# sir_me14 register map
Registers are read-only, no defined reset value unless marked. A register's access mark holds for its fields unless they carry their own. Offsets are from the block's base; lines under a group give offsets from that group; [hi:lo] are bit positions; {n}, {i} and the like mark numbered series; 'fields as' and 'values as' point back to an identical list; <NAME> marks a mode.

## Memory map
0x40000400 SIR size 0x400 — System Initialization Registers.

## SIR — System Initialization Registers.
Base 0x40000400
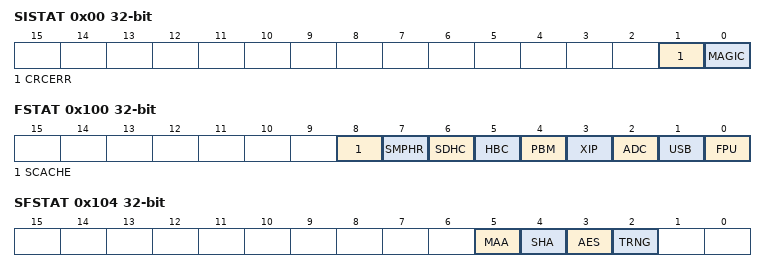
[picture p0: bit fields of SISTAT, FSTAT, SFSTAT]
0x00 SISTAT — System Initialization Status Register.
  [1] CRCERR — CRC Error Status. This bit is set by the system initialization block following power-up.
    on read: 0=noError (No CRC errors occurred during the read of the OTP memory block.); 1=error (A CRC error occurred while reading the OTP. The address of the failure location in the OTP memory is stored in the ERRADDR register.)
  [0] MAGIC — Magic Word Validation. This bit is set by the system initialization block following power-up.
    on read: 0=magicNotSet (Magic word was not set (OTP has not been initialized properly).); 1=magicSet (Magic word was set (OTP contains valid settings).)
0x04 ERRADDR — Read-only field set by the SIB block if a CRC error occurs during the read of the OTP memory. Contains the failing address in OTP memory (when CRCERR equals 1).
  [31:0] ERRADDR
0x54 BTLE_LDO_TRIM_TX rw — BTLE LDO TX Trim register.
  [4:0] TX — TX LDO trim value.
0x5C BTLE_LDO_TRIM_RX rw — BTLE LDO RX Trim register.
  [4:0] RX — RX LDO trim value.
0x100 FSTAT — funcstat register.
  [all] fields
    0=no; 1=yes
  [8] SCACHE — System Cache function.
  [7] SMPHR — SMPHR function.
  [6] SDHC — SDHC function.
  [5] HBC — HBC function.
  [4] PBM — PBM function.
  [3] XIP — XiP function.
  [2] ADC — 10-bit Sigma Delta ADC.
  [1] USB — USB Device.
  [0] FPU — FPU Function.
0x104 SFSTAT — secfuncstat register.
  [all] fields
    0=no; 1=yes
  [5] MAA — MAA function.
  [4] SHA — SHA function.
  [3] AES — AES function.
  [2] TRNG — TRNG function.
